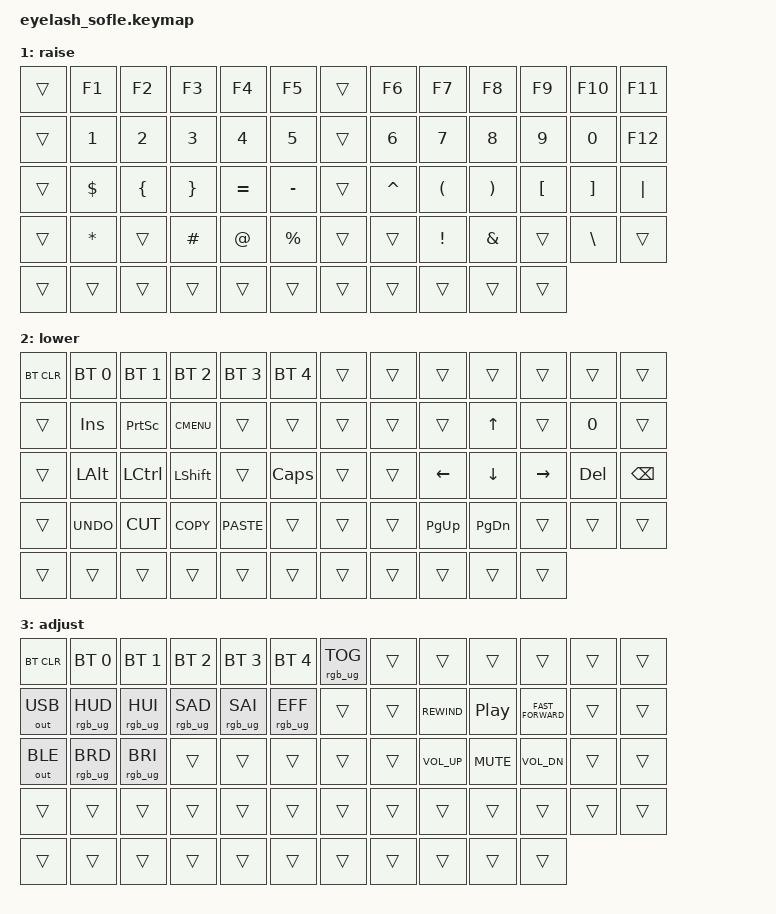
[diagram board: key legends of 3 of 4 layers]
#define ZMK_POINTING_DEFAULT_MOVE_VAL 1200  // 600
#define ZMK_POINTING_DEFAULT_SCRL_VAL 25   // 10

#include <input/processors.dtsi>
#include <zephyr/dt-bindings/input/input-event-codes.h>
#include <behaviors.dtsi>
#include <dt-bindings/zmk/bt.h>
#include <dt-bindings/zmk/keys.h>
#include <dt-bindings/zmk/outputs.h>
#include <dt-bindings/zmk/pointing.h>
#include <dt-bindings/zmk/rgb.h>

&mmv_input_listener { input-processors = <&zip_xy_scaler 2 1>; };

&msc_input_listener { input-processors = <&zip_scroll_scaler 2 1>; };

&msc {
    acceleration-exponent = <1>;      // 0
    time-to-max-speed-ms = <100>;       // 300
    delay-ms = <0>;                   // 0
};

&mmv {
    time-to-max-speed-ms = <500>;
    acceleration-exponent = <1>;
    trigger-period-ms = <16>;
};

&soft_off { hold-time-ms = <2000>; };

/ {
    scroll_encoder: scroll_encoder {
        compatible = "zmk,behavior-sensor-rotate";
        #sensor-binding-cells = <0>;
        bindings = <&msc SCRL_DOWN>, <&msc SCRL_UP>;

        tap-ms = <100>;
    };

    behaviors {
    };

    combos {
        compatible = "zmk,combos";

        softoff {
            bindings = <&soft_off>;
            key-positions = <14 28 40>;
        };
    };

    macros {
        SHIFT_MCLK: SHIFT_MCLK {
            compatible = "zmk,behavior-macro";
            #binding-cells = <0>;
            bindings =
                <&macro_press>,
                <&kp LEFT_SHIFT>,
                <&macro_press>,
                <&mkp MB3>,
                <&macro_pause_for_release>,
                <&macro_release>,
                <&kp LEFT_SHIFT &mkp MB3>;

            label = "SHIFT_MCLK";
        };
    };

    keymap {
        compatible = "zmk,keymap";

        layer0 {
// -----------------------------------------------------------------------------------------------------------------------
// |   `   |  1  |  2  |  3   |  4   |  5   |                   |  6   |  7    |  8    |  9   |   0   | ADJUST |
// |  ESC  |  Q  |  W  |  E   |  R   |  T   |                   |  Y   |  U    |  I    |  O   |   P   | BKSPC |
// |  TAB  |  A  |  S  |  D   |  F   |  G   |                   |  H   |  J    |  K    |  L   |   ;   |   '   |
// | SHIFT |  Z  |  X  |  C   |  V   |  B   |        |  |       |  N   |  M    |  ,    |  .   |   /   | SHIFT |
//               | CTRL | ALT  | GUI | LOWER|  ENTER |  | SPACE | RAISE| GUI   | ALT   | CTRL  |
            bindings = <
&kp GRAVE   &kp N1     &kp N2    &kp N3    &kp N4  &kp N5     &trans &kp N6     &kp N7     &kp N8     &kp N9    &kp N0    &mo 3
&kp ESC     &kp Q      &kp W     &kp E     &kp R   &kp T      &trans &kp Y      &kp U      &kp I      &kp O     &kp P     &kp BSPC
&kp TAB     &kp A      &kp S     &kp D     &kp F   &kp G      &trans &kp H      &kp J      &kp K      &kp L     &kp SEMI  &kp SQT
&kp LSHFT   &kp Z      &kp X     &kp C     &kp V   &kp B      &trans &kp N      &kp M      &kp COMMA &kp DOT    &kp FSLH   &kp RSHFT
&trans      &kp LCTRL  &kp LALT  &kp LGUI  &mo 1   &kp ENTER  &trans &kp SPACE  &mo 2      &kp RGUI   &kp RALT   &kp RCTRL
            >;

            sensor-bindings = <&inc_dec_kp C_VOLUME_UP C_VOL_DN>;
            display-name = "LAYER0";
        };

        raise {
// -----------------------------------------------------------------------------------------------------------------------
// |       |  F1 |  F2 |  F3  |  F4  |  F5  |       |                |       |  F6  |  F7   |  F8   |  F9  |  F10  |  F11  |
// |       |  1  |  2  |  3   |  4   |  5   |       |                |       |  6   |  7    |  8    |  9   |   0   |  F12  |
// |       |  $  |  {  |  }   |  =   |  -   |       |                |       |  ^   |  (    |  )    |  [   |   ]   |   |   |
// |       |  *  |     |  #   |  @   |   %  |       |                |       |      |  !    |   &   |      |  /     |       |
// |       |     |      |      |      |        |                |       |      |       |       |      |
            bindings = <
&trans    &kp F1    &kp F2     &kp F3    &kp F4     &kp F5     &trans      &kp F6    &kp F7    &kp F8    &kp F9    &kp F10   &kp F11
&trans    &kp N1    &kp N2     &kp N3    &kp N4     &kp N5     &trans      &kp N6    &kp N7    &kp N8    &kp N9    &kp N0    &kp F12
&trans    &kp DLLR  &kp LBRC  &kp RBRC   &kp EQUAL  &kp MINUS  &trans      &kp CARET &kp LPAR  &kp RPAR  &kp LBKT  &kp RBKT  &kp PIPE
&trans    &kp ASTRK &trans    &kp HASH  &kp AT      &kp PRCNT  &trans      &trans    &kp EXCL  &kp AMPS  &trans &kp BSLH    &trans
&trans    &trans    &trans     &trans    &trans     &trans     &trans      &trans    &trans    &trans    &trans
            >;

            display-name = "raise";
            sensor-bindings = <&scroll_encoder>;
        };

        lower {
// -----------------------------------------------------------------------------------------------------------------------
// | BTCLR | BT1  | BT2  |  BT3  |  BT4  |  BT5 |       |                |       |      |      |   ^   |      |       |       |
// |       | INS  | PSCR | GUI   |       |      |       |                |       |      |      |   ^   |      |       |       |
// |       | ALT  | CTRL | SHIFT |       | CAPS |       |                |       |      |   <- |   v   |  ->  |  DEL  | BKSPC |
// |       | UNDO | CUT  | COPY  | PASTE |      |       |                |       |      | PGUP | PGDN  |      |       |       |
// |       |      |       |       |      |      |                |      |      |      |       |      |
            bindings = <
&bt BT_CLR &bt BT_SEL 0 &bt BT_SEL 1 &bt BT_SEL 2 &bt BT_SEL 3 &bt BT_SEL 4 &trans  &trans &trans    &trans    &trans    &trans  &trans
&trans     &kp INS      &kp PSCRN    &kp K_CMENU  &trans       &trans       &trans  &trans &trans    &kp UP    &trans    &kp N0  &trans
&trans     &kp LALT     &kp LCTRL    &kp LSHFT    &trans       &kp CLCK     &trans  &trans &kp LEFT  &kp DOWN  &kp RIGHT &kp DEL &kp BSPC
&trans     &kp K_UNDO   &kp K_CUT    &kp K_COPY   &kp K_PASTE  &trans       &trans  &trans &kp PG_UP &kp PG_DN &trans    &trans  &trans
&trans     &trans       &trans       &trans       &trans       &trans       &trans  &trans &trans    &trans    &trans
            >;

            display-name = "lower";
            sensor-bindings = <&scroll_encoder>;
        };

        adjust {
// -----------------------------------------------------------------------------------------------------------------------
// | BTCLR  |  BT1    |  BT2    |   BT3   |   BT4   |   BT5   |       |                |       |      |      |       |      |       |       |
// | OUT_USB| RGB_HUD | RGB_HUI | RGB_SAD | RGB_SAI | RGB_EFF |       |                |       |      |  REW  |  PLAY |  FF  |       |       |
// |OUT_BLE | RGB_BRD | RGB_BRI |         |         |         |       |                |       |      |VOLUP | MUTE  |VOLDOWN|       |       |
// |        |         |         |         |         |         |       |                |       |      |      |       |      |       |       |
// |        |         |         |         |         |         |                |      |      |      |       |      |
            bindings = <
&bt BT_CLR   &bt BT_SEL 0    &bt BT_SEL 1    &bt BT_SEL 2 &bt BT_SEL 3    &bt BT_SEL 4    &rgb_ug RGB_TOG  &trans &trans &trans &trans &trans &trans
&out OUT_USB &rgb_ug RGB_HUD &rgb_ug RGB_HUI &rgb_ug RGB_SAD &rgb_ug RGB_SAI &rgb_ug RGB_EFF &trans        &trans &kp C_REWIND &kp C_PLAY_PAUSE &kp C_FAST_FORWARD &trans &trans
&out OUT_BLE &rgb_ug RGB_BRD &rgb_ug RGB_BRI &trans       &trans          &trans          &trans           &trans &kp C_VOL_UP  &kp C_MUTE &kp C_VOL_DN &trans &trans
&trans       &trans          &trans          &trans       &trans          &trans          &trans           &trans &trans &trans &trans &trans &trans
&trans       &trans          &trans          &trans       &trans          &trans          &trans           &trans &trans &trans &trans
            >;

            display-name = "adjust";
            sensor-bindings = <&scroll_encoder>;
        };
    };
};
